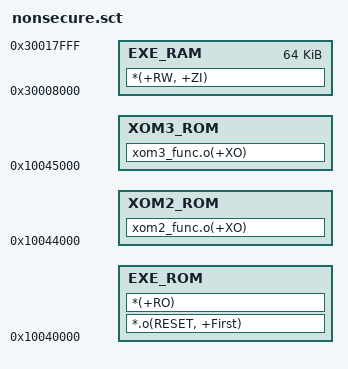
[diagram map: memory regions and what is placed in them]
   
LR_ROM 0x10040000 0x10000
{

    EXE_ROM +0
    {
        *.o(RESET, +First)
        *(+RO)
    }
    
    EXE_RAM 0x30008000 0x10000
    {
        *(+RW, +ZI)
    }
	
}



LR_XOM2 0x10044000 0x1000
{
    XOM2_ROM +0
    {
        xom2_func.o(+XO)
    }
}

LR_XOM3 0x10045000 0x1000
{
    XOM3_ROM +0
    {
        xom3_func.o(+XO)
    }
}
